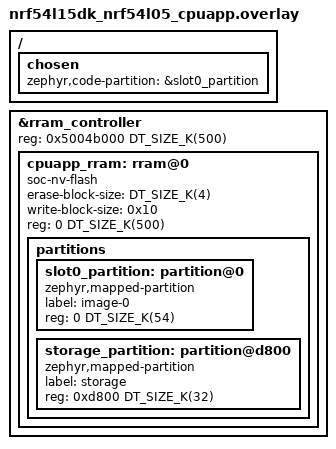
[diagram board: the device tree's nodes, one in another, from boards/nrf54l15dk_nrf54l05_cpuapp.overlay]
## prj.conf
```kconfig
#
# Copyright (c) 2021-2023 Nordic Semiconductor ASA
#
# SPDX-License-Identifier: LicenseRef-Nordic-5-Clause
#
CONFIG_ZTEST=y
CONFIG_FPROTECT=y
CONFIG_FPROTECT_APP=n

CONFIG_DEBUG_OPTIMIZATIONS=y
# Ensure that flash writes are allowed
CONFIG_FLASH=y
CONFIG_MPU_ALLOW_FLASH_WRITE=y

# Ensure that 'storage' partition is defined, so that we have somewhere legal
# to write.
CONFIG_FLASH_MAP=y
CONFIG_SETTINGS=y
CONFIG_NVS=y
```

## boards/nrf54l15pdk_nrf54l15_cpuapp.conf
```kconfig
CONFIG_PARTITION_MANAGER_ENABLED=n
```

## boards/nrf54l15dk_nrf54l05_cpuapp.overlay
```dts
/*
 * Copyright (c) 2026 Nordic Semiconductor ASA
 *
 * SPDX-License-Identifier: LicenseRef-Nordic-5-Clause
 */
/ {
	chosen {
		zephyr,code-partition = &slot0_partition;
	};
};

/delete-node/ &cpuapp_rram;

&rram_controller {
	reg = <0x5004b000 DT_SIZE_K(500)>;

	cpuapp_rram: rram@0 {
		compatible = "soc-nv-flash";
		erase-block-size = <DT_SIZE_K(4)>;
		write-block-size = <0x10>;
		reg = <0 DT_SIZE_K(500)>;

		partitions {
			ranges;
			#address-cells = <1>;
			#size-cells = <1>;

			slot0_partition: partition@0 {
				compatible = "zephyr,mapped-partition";
				label = "image-0";
				reg = <0 DT_SIZE_K(54)>;
			};

			storage_partition: partition@d800 {
				compatible = "zephyr,mapped-partition";
				label = "storage";
				reg = <0xd800 DT_SIZE_K(32)>;
			};
		};
	};
};
```

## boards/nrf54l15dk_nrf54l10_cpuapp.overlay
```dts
/*
 * Copyright (c) 2026 Nordic Semiconductor ASA
 *
 * SPDX-License-Identifier: LicenseRef-Nordic-5-Clause
 */
/ {
	chosen {
		zephyr,code-partition = &slot0_partition;
	};
};

/delete-node/ &cpuapp_rram;

&rram_controller {
	reg = <0x5004b000 DT_SIZE_K(1012)>;

	cpuapp_rram: rram@0 {
		compatible = "soc-nv-flash";
		erase-block-size = <DT_SIZE_K(4)>;
		write-block-size = <0x10>;
		reg = <0 DT_SIZE_K(1012)>;

		partitions {
			ranges;
			#address-cells = <1>;
			#size-cells = <1>;

			slot0_partition: partition@0 {
				compatible = "zephyr,mapped-partition";
				label = "image-0";
				reg = <0 DT_SIZE_K(54)>;
			};

			storage_partition: partition@d800 {
				compatible = "zephyr,mapped-partition";
				label = "storage";
				reg = <0xd800 DT_SIZE_K(32)>;
			};
		};
	};
};
```

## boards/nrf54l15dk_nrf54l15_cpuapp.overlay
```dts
/ {
	chosen {
		zephyr,code-partition = &slot0_partition;
	};
};

/delete-node/ &cpuapp_rram;

&rram_controller {
	reg = <0x5004b000 0x17d000>;

	cpuapp_rram: rram@0 {
		compatible = "soc-nv-flash";
		erase-block-size = <0x1000>;
		write-block-size = <0x10>;
		reg = <0x0 0x17d000>;

		partitions {
			ranges;
			#address-cells = <0x1>;
			#size-cells = <0x1>;

			slot0_partition: partition@0 {
				compatible = "zephyr,mapped-partition";
				label = "image-0";
				reg = <0x0 0xd800>;
			};

			storage_partition: partition@175000 {
				compatible = "zephyr,mapped-partition";
				label = "storage";
				reg = <0x175000 0x8000>;
			};
		};
	};
};
```

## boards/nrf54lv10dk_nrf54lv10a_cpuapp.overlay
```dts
/ {
	chosen {
		zephyr,code-partition = &slot0_partition;
	};
};

/delete-node/ &cpuapp_rram;

&rram_controller {
	cpuapp_rram: rram@0 {
		compatible = "soc-nv-flash";
		erase-block-size = <DT_SIZE_K(4)>;
		write-block-size = <0x10>;
		reg = <0 DT_SIZE_K(1012)>;

		partitions {
			ranges;
			#address-cells = <1>;
			#size-cells = <1>;

			slot0_partition: partition@0 {
				compatible = "zephyr,mapped-partition";
				label = "image-0";
				reg = <0 DT_SIZE_K(54)>;
			};

			storage_partition: partition@f4000 {
				compatible = "zephyr,mapped-partition";
				label = "storage";
				reg = <0xf4000 DT_SIZE_K(36)>;
			};
		};
	};
};
```

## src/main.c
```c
/*
 * Copyright (c) 2021 Nordic Semiconductor ASA
 *
 * SPDX-License-Identifier: LicenseRef-Nordic-5-Clause
 */

#include <zephyr/ztest.h>
#include <zephyr/device.h>
#include <fprotect.h>
#include <string.h>
#include <zephyr/drivers/flash.h>
#include <zephyr/storage/flash_map.h>

#define STORAGE_PARTITION storage_partition

#define STORAGE_AREA_DEVICE PARTITION_DEVICE(STORAGE_PARTITION)
#define STORAGE_AREA_ADDRESS PARTITION_OFFSET(STORAGE_PARTITION)

BUILD_ASSERT(STORAGE_AREA_ADDRESS % CONFIG_FPROTECT_BLOCK_SIZE == 0,
	"storage area isn't properly aligned with protection region");

static uint32_t expected_fatal;
static uint32_t actual_fatal;

void k_sys_fatal_error_handler(unsigned int reason, const struct arch_esf *pEsf)
{
	printk("Caught system error -- reason %d\n", reason);
	actual_fatal++;
}

ZTEST(fprotect_test, test_writing_to_app_image)
{
	/* Any random data for writing */
	static uint8_t val[16];

	printf("Perform a legal flash write to show that it is supported\n");
	int err = flash_write(STORAGE_AREA_DEVICE, STORAGE_AREA_ADDRESS, val, sizeof(val));

	zassert_equal(err, 0, "Failed when writing to legal flash area");
	zassert_equal(expected_fatal, actual_fatal, "An unexpected fatal error has occurred.\n");
	expected_fatal++;
	printf("Enable protection over single storage area block and attempt writing into it\n");
	err = fprotect_area(STORAGE_AREA_ADDRESS, CONFIG_FPROTECT_BLOCK_SIZE);
	zassert_equal(err, 0, "fprotect_area() exited with error");
	printf("The next lines should be a BUS FAULT\n");
	flash_write(STORAGE_AREA_DEVICE, STORAGE_AREA_ADDRESS, val, sizeof(val));
	zassert_unreachable("Should have BUS FAULTed before coming here.");
}

static void check_fatal(void *unused)
{
	zassert_equal(expected_fatal, actual_fatal,
			"The wrong number of fatal error has occurred (e:%d != a:%d).\n",
			expected_fatal, actual_fatal);
}

ZTEST_SUITE(fprotect_test, NULL, NULL, NULL, check_fatal, NULL);
```
